# ATSAML22N18A register map
Vendor: Atmel Corporation; Series: SAML22; File version: A
CPU: CM0+ r0p1, little endian, MPU, no FPU, VTOR, 2 interrupt priority bits
Registers are 32-bit, read-write, reset 0x0 unless marked. A register's access mark holds for its fields unless they carry their own. Offsets are from the block's base; [hi:lo] are bit positions; {n}, {i} and the like mark numbered series; 'fields as' and 'values as' point back to an identical list.

## TAL — Trigger Allocator
Base 0x40003000; register names take the prefix TAL_
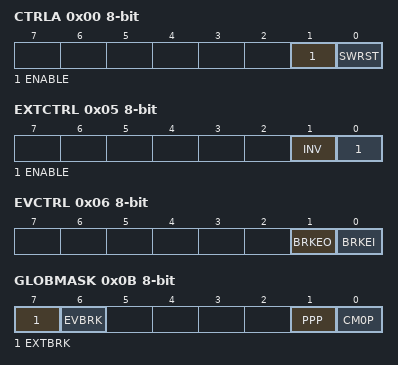
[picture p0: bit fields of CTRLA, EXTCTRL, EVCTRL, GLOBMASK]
0x00 CTRLA 8-bit — Control A
  [1] ENABLE
  [0] SWRST — Software Reset
0x04 RSTCTRL 8-bit — Reset Control
0x05 EXTCTRL 8-bit — External Break Control
  [1] INV — Invert BRK Pin
  [0] ENABLE — Enable BRK Pin
0x06 EVCTRL 8-bit — Event Control
  [1] BRKEO — Break Output Event Enable
  [0] BRKEI — Break Input Event Enable
0x08 INTENCLR 8-bit — Interrupt Enable Clear
  [0] BRK — Break Interrupt Enable
0x09 INTENSET 8-bit — Interrupt Enable Set
  [0] BRK — Break Interrupt Enable
0x0A INTFLAG 8-bit — Interrupt Flag Status and Clear
  [0] BRK — Break
0x0B GLOBMASK 8-bit — Global Break Requests Mask
  [7] EXTBRK — External Break Master
  [6] EVBRK — Event Break Master
  [1] PPP — PPP Break Master
  [0] CM0P — CM0P Break Master
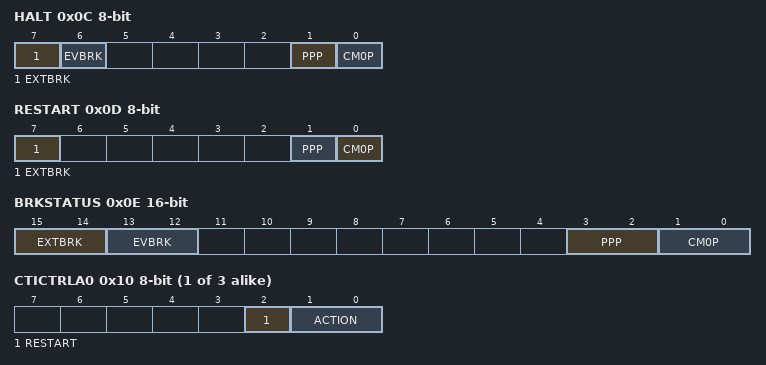
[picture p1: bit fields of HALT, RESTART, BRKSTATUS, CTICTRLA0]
0x0C HALT 8-bit wo — Debug Halt Request
  fields as GLOBMASK
0x0D RESTART 8-bit wo — Debug Restart Request
  [7] EXTBRK — External Break Master
  [1] PPP — PPP Break Master
  [0] CM0P — CM0P Break Master
0x0E BRKSTATUS 16-bit ro — Break Request Status
  [15:14] EXTBRK — External Break Request
  [13:12] EVBRK — Event Break Request
  [3:2] PPP — PPP Break Request
  [1:0] CM0P — CM0P Break Request
{0x10+2i} CTICTRLA{i} (i=0..2) 8-bit — Cross-Trigger Interface n Control A
  [2] RESTART — Action when global restart issued
    0=RESTART (Restart when requested); 1=IGNORE (Ignore restart request)
  [1:0] ACTION — Action when global break issued
    0=BREAK (Break when requested); 1=INTERRUPT (Trigger DBG interrupt instead of break); 2=IGNORE (Ignore break request)
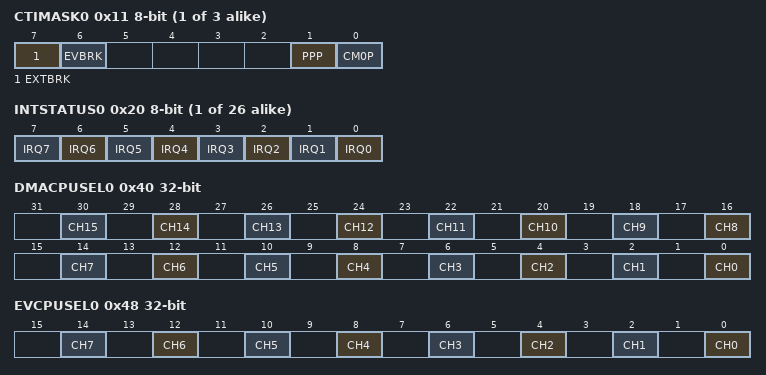
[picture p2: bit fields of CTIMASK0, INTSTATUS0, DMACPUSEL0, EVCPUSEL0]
{0x11+2i} CTIMASK{i} (i=0..2) 8-bit — Cross-Trigger Interface n Mask
  fields as GLOBMASK
{0x20+i} INTSTATUS{i} (i=0..25) 8-bit ro — Interrupt n Status
  [n] IRQ{n} (n=0..7) — Interrupt Status for Interrupt Request {n} within Interrupt n
0x40 DMACPUSEL0 — DMA Channel Interrupts CPU Select 0
  [2n] CH{n} (n=0..15) — DMA Channel {n} Interrupt CPU Select
0x48 EVCPUSEL0 — EVSYS Channel Interrupts CPU Select 0
  [2n] CH{n} (n=0..7) — Event Channel {n} Interrupt CPU Select
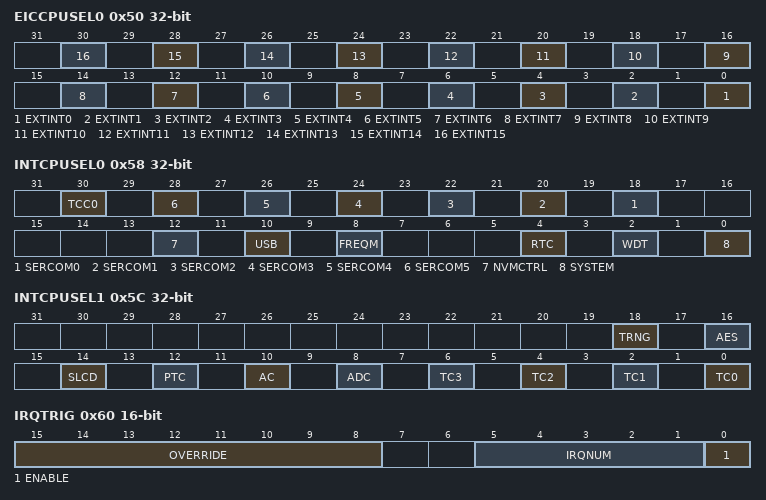
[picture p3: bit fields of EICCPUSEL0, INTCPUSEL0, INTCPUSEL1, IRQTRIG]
0x50 EICCPUSEL0 — EIC External Interrupts CPU Select 0
  [2n] EXTINT{n} (n=0..15) — External Interrupt {n} CPU Select
0x58 INTCPUSEL0 — Interrupts CPU Select 0
  [30] TCC0 — TCC0 Interrupt CPU Select
  [2n+18] SERCOM{n} (n=0..5) — SERCOM{n} Interrupt CPU Select
  [12] NVMCTRL — NVMCTRL Interrupt CPU Select
  [10] USB — USB Interrupt CPU Select
  [8] FREQM — FREQM Interrupt CPU Select
  [4] RTC — RTC Interrupt CPU Select
  [2] WDT — WDT Interrupt CPU Select
  [0] SYSTEM — SYSTEM Interrupt CPU Select
0x5C INTCPUSEL1 — Interrupts CPU Select 1
  [18] TRNG — TRNG Interrupt CPU Select
  [16] AES — AES Interrupt CPU Select
  [14] SLCD — SLCD Interrupt CPU Select
  [12] PTC — PTC Interrupt CPU Select
  [10] AC — AC Interrupt CPU Select
  [8] ADC — ADC Interrupt CPU Select
  [2n] TC{n} (n=0..3) — TC{n} Interrupt CPU Select
0x60 IRQTRIG 16-bit — Interrupt Trigger
  [15:8] OVERRIDE — Interrupt Request Override Value
  [5:1] IRQNUM — Interrupt Request Number
  [0] ENABLE — Trigger Enable
{0x64+4i} CPUIRQS{i} (i=0..0) ro — Interrupt Status for CPU n
  [25:0] CPUIRQS — Interrupt Requests for CPU n

## TRNG — True Random Generator
Base 0x42004400; register names take the prefix TRNG_
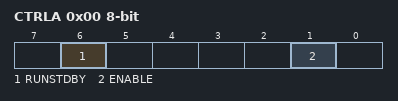
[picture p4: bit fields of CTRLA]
0x00 CTRLA 8-bit — Control A
  [6] RUNSTDBY — Run in Standby
  [1] ENABLE
0x04 EVCTRL 8-bit — Event Control
  [0] DATARDYEO — Data Ready Event Output
0x08 INTENCLR 8-bit — Interrupt Enable Clear
  [0] DATARDY — Data Ready Interrupt Enable
0x09 INTENSET 8-bit — Interrupt Enable Set
  [0] DATARDY — Data Ready Interrupt Enable
0x0A INTFLAG 8-bit — Interrupt Flag Status and Clear
  [0] DATARDY — Data Ready Interrupt Flag
0x20 DATA ro — Output Data

## WDT — Watchdog Timer
Base 0x40002000; register names take the prefix WDT_
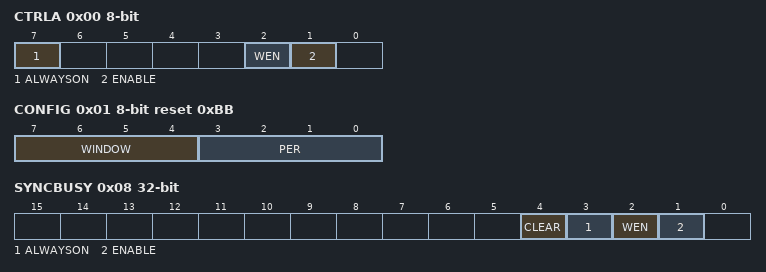
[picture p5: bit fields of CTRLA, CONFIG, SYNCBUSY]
0x00 CTRLA 8-bit — Control
  [7] ALWAYSON
  [2] WEN — Watchdog Timer Window Mode Enable
  [1] ENABLE
0x01 CONFIG 8-bit reset 0xBB — Configuration
  [7:4] WINDOW — Window Mode Time-Out Period
    0=CYC8 (8 clock cycles); 1=CYC16 (16 clock cycles); 2=CYC32 (32 clock cycles); 3=CYC64 (64 clock cycles); 4=CYC128 (128 clock cycles); 5=CYC256 (256 clock cycles); 6=CYC512 (512 clock cycles); 7=CYC1024 (1024 clock cycles); 8=CYC2048 (2048 clock cycles); 9=CYC4096 (4096 clock cycles); 10=CYC8192 (8192 clock cycles); 11=CYC16384 (16384 clock cycles)
  [3:0] PER — Time-Out Period
    values as WINDOW
0x02 EWCTRL 8-bit reset 0xB — Early Warning Interrupt Control
  [3:0] EWOFFSET — Early Warning Interrupt Time Offset
    values as CONFIG.WINDOW
0x04 INTENCLR 8-bit — Interrupt Enable Clear
  [0] EW — Early Warning Interrupt Enable
0x05 INTENSET 8-bit — Interrupt Enable Set
  [0] EW — Early Warning Interrupt Enable
0x06 INTFLAG 8-bit — Interrupt Flag Status and Clear
  [0] EW — Early Warning
0x08 SYNCBUSY ro — Synchronization Busy
  [4] CLEAR — Clear Busy
  [3] ALWAYSON — Always-On Busy
  [2] WEN — Window Enable Busy
  [1] ENABLE — Enable Busy
0x0C CLEAR 8-bit wo
  [7:0] CLEAR — Watchdog Clear
    165=KEY (Clear Key)

## Notices in the file
Atmel Microcontroller Software Support
Copyright (c) 2015, Atmel Corporation
All rights reserved.
Redistribution and use in source and binary forms, with or without
modification, are permitted provided that the following condition is met:
- Redistributions of source code must retain the above copyright notice,
this list of conditions and the disclaimer below.
Atmel's name may not be used to endorse or promote products derived from
this software without specific prior written permission.
DISCLAIMER: THIS SOFTWARE IS PROVIDED BY ATMEL "AS IS" AND ANY EXPRESS OR
IMPLIED WARRANTIES, INCLUDING, BUT NOT LIMITED TO, THE IMPLIED WARRANTIES OF
MERCHANTABILITY, FITNESS FOR A PARTICULAR PURPOSE AND NON-INFRINGEMENT ARE
DISCLAIMED. IN NO EVENT SHALL ATMEL BE LIABLE FOR ANY DIRECT, INDIRECT,
INCIDENTAL, SPECIAL, EXEMPLARY, OR CONSEQUENTIAL DAMAGES (INCLUDING, BUT NOT
LIMITED TO, PROCUREMENT OF SUBSTITUTE GOODS OR SERVICES; LOSS OF USE, DATA,
OR PROFITS; OR BUSINESS INTERRUPTION) HOWEVER CAUSED AND ON ANY THEORY OF
LIABILITY, WHETHER IN CONTRACT, STRICT LIABILITY, OR TORT (INCLUDING
NEGLIGENCE OR OTHERWISE) ARISING IN ANY WAY OUT OF THE USE OF THIS SOFTWARE,
EVEN IF ADVISED OF THE POSSIBILITY OF SUCH DAMAGE.
